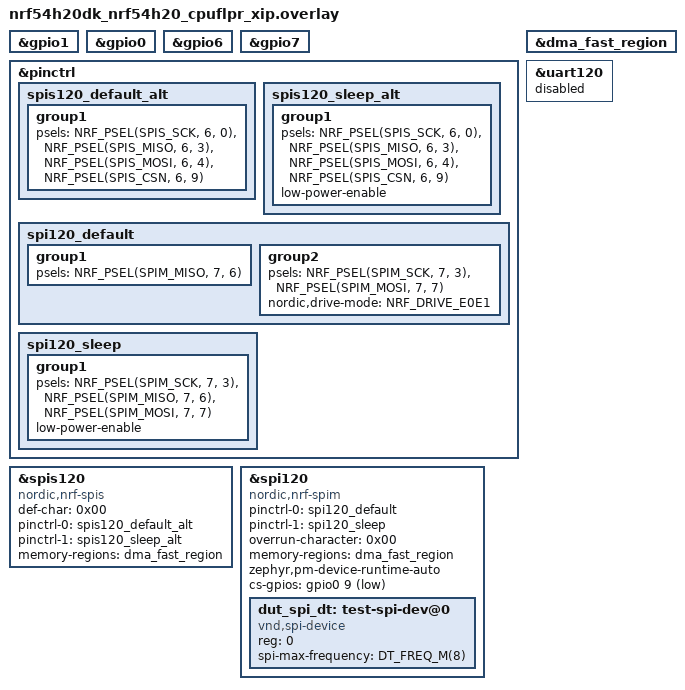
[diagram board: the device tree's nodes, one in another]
/*
 * Copyright (c) 2026 Nordic Semiconductor ASA
 *
 * SPDX-License-Identifier: Apache-2.0
 */

#include <zephyr/dt-bindings/gpio/gpio.h>

&gpio1 {
	status = "okay";
};

&gpio0 {
	status = "okay";
};

&gpio6 {
	status = "okay";
};

&gpio7 {
	status = "okay";
};

&pinctrl {
	spis120_default_alt: spis120_default_alt {
		group1 {
			psels = <NRF_PSEL(SPIS_SCK, 6, 0)>,
				<NRF_PSEL(SPIS_MISO, 6, 3)>,
				<NRF_PSEL(SPIS_MOSI, 6, 4)>,
				<NRF_PSEL(SPIS_CSN, 6, 9)>;
		};
	};

	spis120_sleep_alt: spis120_sleep_alt {
		group1 {
			psels = <NRF_PSEL(SPIS_SCK, 6, 0)>,
				<NRF_PSEL(SPIS_MISO, 6, 3)>,
				<NRF_PSEL(SPIS_MOSI, 6, 4)>,
				<NRF_PSEL(SPIS_CSN, 6, 9)>;
			low-power-enable;
		};
	};

	spi120_default: spi120_default {
		group1 {
			psels = <NRF_PSEL(SPIM_MISO, 7, 6)>;
		};

		group2 {
			psels = <NRF_PSEL(SPIM_SCK, 7, 3)>,
				<NRF_PSEL(SPIM_MOSI, 7, 7)>;
			nordic,drive-mode = <NRF_DRIVE_E0E1>;
		};
	};

	spi120_sleep: spi120_sleep {
		group1 {
			psels = <NRF_PSEL(SPIM_SCK, 7, 3)>,
				<NRF_PSEL(SPIM_MISO, 7, 6)>,
				<NRF_PSEL(SPIM_MOSI, 7, 7)>;
			low-power-enable;
		};
	};
};

&dma_fast_region {
	status = "okay";
};

dut_spis: &spis120 {
	compatible = "nordic,nrf-spis";
	status = "okay";
	def-char = <0x00>;
	pinctrl-0 = <&spis120_default_alt>;
	pinctrl-1 = <&spis120_sleep_alt>;
	pinctrl-names = "default", "sleep";
	memory-regions = <&dma_fast_region>;
};

&spi120 {
	compatible = "nordic,nrf-spim";
	status = "okay";
	pinctrl-0 = <&spi120_default>;
	pinctrl-1 = <&spi120_sleep>;
	pinctrl-names = "default", "sleep";
	overrun-character = <0x00>;
	memory-regions = <&dma_fast_region>;
	zephyr,pm-device-runtime-auto;
	cs-gpios = <&gpio0 9 GPIO_ACTIVE_LOW>;

	dut_spi_dt: test-spi-dev@0 {
		compatible = "vnd,spi-device";
		reg = <0>;
		spi-max-frequency = <DT_FREQ_M(8)>;
	};
};

&uart120 {
	status = "disabled";
};
